# CH32V203G6U6 register map
Vendor: WCH; File version: 0.1.0
CPU: QingKe V4B V4B, little endian, no MPU, no FPU, vendor SysTick, 4 interrupt priority bits
Registers are 16-bit, read-write, reset 0x0 unless marked. A register's access mark holds for its fields unless they carry their own. Offsets are from the block's base; [hi:lo] are bit positions; lines under a group give offsets from that group; {n}, {i} and the like mark numbered series.

## CAN1 — bxCAN controller
Base 0x40006400
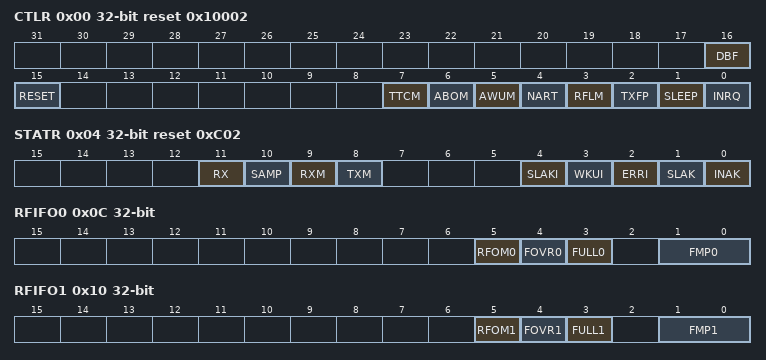
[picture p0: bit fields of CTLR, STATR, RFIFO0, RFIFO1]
0x00 CTLR 32-bit reset 0x10002 — CAN Master control register
  [16] DBF — Debug freeze
  [15] RESET — Software master reset
  [7] TTCM — Time triggered communication mode
  [6] ABOM — Automatic bus-off management
  [5] AWUM — Automatic wakeup mode
  [4] NART — No automatic retransmission
  [3] RFLM — Receive FIFO locked mode
  [2] TXFP — Transmit FIFO priority
  [1] SLEEP — Sleep mode request
  [0] INRQ — Initialization request
0x04 STATR 32-bit reset 0xC02 — CAN master status register
  [11] RX ro — Rx signal
  [10] SAMP ro — Last sample point
  [9] RXM ro — Receive mode
  [8] TXM ro — Transmit mode
  [4] SLAKI — Sleep acknowledge interrupt
  [3] WKUI — Wakeup interrupt
  [2] ERRI — Error interrupt
  [1] SLAK ro — Sleep acknowledge
  [0] INAK ro — Initialization acknowledge
0x08 TSTATR 32-bit reset 0x1C000000 — CAN transmit status register
  [31] LOW2 ro — Lowest priority flag for mailbox 2
  [30] LOW1 ro — Lowest priority flag for mailbox 1
  [31:29] LOW
  [29] LOW0 ro — Lowest priority flag for mailbox 0
  [28] TME2 ro — Transmit mailbox 2 empty
  [27] TME1 ro — Transmit mailbox 1 empty
  [28:26] TME
  [26] TME0 ro — Transmit mailbox 0 empty
  [25:24] CODE ro — Mailbox code
  [23] ABRQ2 — Abort request for mailbox 2
  [19] TERR2 — Transmission error of mailbox 2
  [18] ALST2 — Arbitration lost for mailbox 2
  [17] TXOK2 — Transmission OK of mailbox 2
  [16] RQCP2 — Request completed mailbox2
  [15] ABRQ1 — Abort request for mailbox 1
  [11] TERR1 — Transmission error of mailbox1
  [10] ALST1 — Arbitration lost for mailbox1
  [9] TXOK1 — Transmission OK of mailbox1
  [8] RQCP1 — Request completed mailbox1
  [7] ABRQ0 — Abort request for mailbox0
  [3] TERR0 — Transmission error of mailbox0
  [2] ALST0 — Arbitration lost for mailbox0
  [1] TXOK0 — Transmission OK of mailbox0
  [0] RQCP0 — Request completed mailbox0
0x0C RFIFO0 32-bit — CAN receive FIFO 0 register
  [5] RFOM0 — Release FIFO 0 output mailbox
  [4] FOVR0 — FIFO 0 overrun
  [3] FULL0 — FIFO 0 full
  [1:0] FMP0 ro — FIFO 0 message pending
0x10 RFIFO1 32-bit — CAN receive FIFO 1 register
  [5] RFOM1 — Release FIFO 1 output mailbox
  [4] FOVR1 — FIFO 1 overrun
  [3] FULL1 — FIFO 1 full
  [1:0] FMP1 ro — FIFO 1 message pending
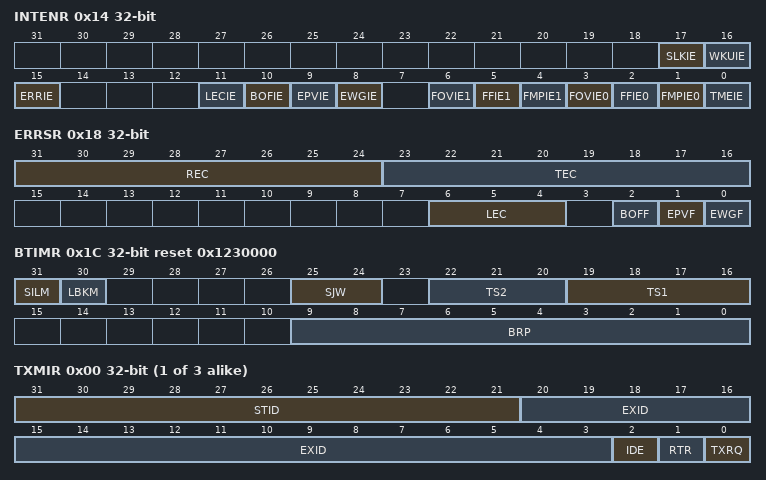
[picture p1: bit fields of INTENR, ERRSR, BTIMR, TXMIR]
0x14 INTENR 32-bit — CAN interrupt enable register
  [17] SLKIE — Sleep interrupt enable
  [16] WKUIE — Wakeup interrupt enable
  [15] ERRIE — Error interrupt enable
  [11] LECIE — Last error code interrupt enable
  [10] BOFIE — Bus-off interrupt enable
  [9] EPVIE — Error passive interrupt enable
  [8] EWGIE — Error warning interrupt enable
  [6] FOVIE1 — FIFO overrun interrupt enable
  [5] FFIE1 — FIFO full interrupt enable
  [4] FMPIE1 — FIFO message pending interrupt enable
  [3] FOVIE0 — FIFO overrun interrupt enable
  [2] FFIE0 — FIFO full interrupt enable
  [1] FMPIE0 — FIFO message pending interrupt enable
  [0] TMEIE — Transmit mailbox empty interrupt enable
0x18 ERRSR 32-bit — CAN error status register
  [31:24] REC ro — Receive error counter
  [23:16] TEC ro — Least significant byte of the 9-bit transmit error counter
  [6:4] LEC — Last error code
  [2] BOFF ro — Bus-off flag
  [1] EPVF ro — Error passive flag
  [0] EWGF ro — Error warning flag
0x1C BTIMR 32-bit reset 0x1230000 — CAN bit timing register
  [31] SILM — Silent mode (debug)
  [30] LBKM — Loop back mode (debug)
  [25:24] SJW — Resynchronization jump width
  [22:20] TS2 — Time segment 2
  [19:16] TS1 — Time segment 1
  [9:0] BRP — Baud rate prescaler
{0x180+0x10*i} TxMailBox{i} (i=0..2) group
  0x00 TXMIR 32-bit — CAN TX mailbox identifier register
    [31:21] STID — Standard identifier
    [20:3] EXID — extended identifier
    [2] IDE — Identifier extension
    [1] RTR — Remote transmission request
    [0] TXRQ — Transmit mailbox request
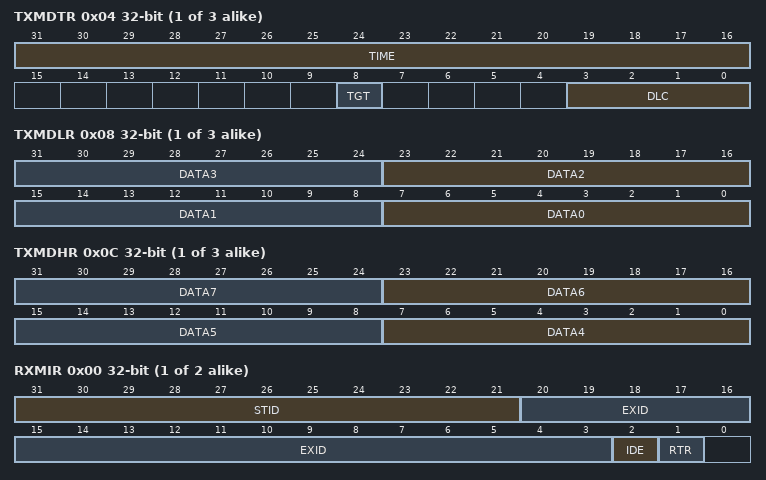
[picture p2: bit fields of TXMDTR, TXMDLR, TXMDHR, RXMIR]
  0x04 TXMDTR 32-bit — CAN mailbox data length control and time stamp register
    [31:16] TIME — Message time stamp
    [8] TGT — Transmit global time
    [3:0] DLC — Data length code
  0x08 TXMDLR 32-bit — CAN mailbox data low register
    [8n+7:8n] DATA{n} (n=0..3) — Data byte {n}
  0x0C TXMDHR 32-bit — CAN mailbox data high register
    [8n-25:8n-32] DATA{n} (n=4..7) — Data byte {n}
{0x1B0+0x10*i} FIFOMailBox{i} (i=0..1) group
  0x00 RXMIR 32-bit — CAN receive FIFO mailbox identifier register
    [31:21] STID ro — Standard identifier
    [20:3] EXID ro — extended identifier
    [2] IDE ro — Identifier extension
    [1] RTR ro — Remote transmission request
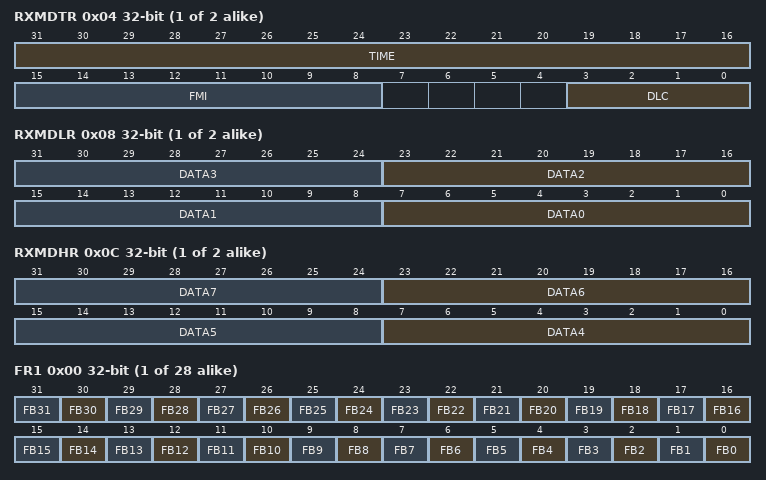
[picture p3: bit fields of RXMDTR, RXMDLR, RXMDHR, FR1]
  0x04 RXMDTR 32-bit — CAN receive FIFO mailbox data length control and time stamp register
    [31:16] TIME ro — Message time stamp
    [15:8] FMI ro — Filter match index
    [3:0] DLC ro — Data length code
  0x08 RXMDLR 32-bit — CAN receive FIFO mailbox data low register
    [8n+7:8n] DATA{n} ro (n=0..3) — Data Byte {n}
  0x0C RXMDHR 32-bit — CAN receive FIFO mailbox data high register
    [8n-25:8n-32] DATA{n} ro (n=4..7)
0x200 FCTLR 32-bit reset 0x2A1C0E01 — CAN filter master register
  [0] FINIT — Filter init mode
0x204 FMCFGR 32-bit — CAN filter mode register
  [27:0] FBM
0x20C FSCFGR 32-bit — CAN filter scale register
  [27:0] FSC
0x214 FAFIFOR 32-bit — CAN filter FIFO assignment register
  [27:0] FFA
0x21C FWR 32-bit — CAN filter activation register
  [27:0] FACT
{0x240+8i} FilterRegister{i} (i=0..27) group
  0x00 FR1 32-bit — Filter bank 0 register 1
    [n] FB{n} (n=0..31) — Filter bits
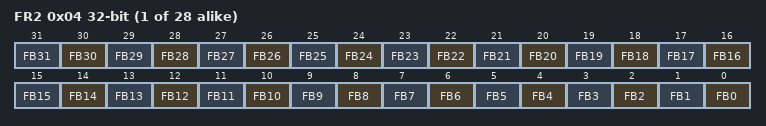
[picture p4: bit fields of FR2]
  0x04 FR2 32-bit — Filter bank 0 register 2
    [n] FB{n} (n=0..31) — Filter bits
